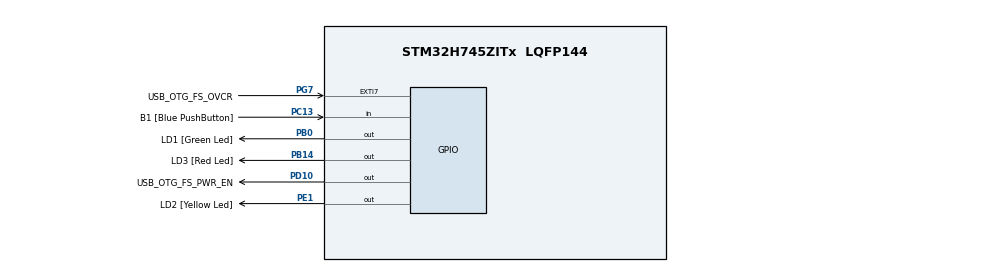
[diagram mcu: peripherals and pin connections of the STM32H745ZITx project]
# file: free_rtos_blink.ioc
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CortexM4.IPs=FATFS_M4\:I,FREERTOS_M4\:I,IWDG2\:I,RCC,WWDG2\:I,DMA,BDMA,MDMA,NVIC2\:I,DEBUG,USB_DEVICE_M4\:I,USB_HOST_M4\:I,PDM2PCM_M4\:I,PWR,RESMGR_UTILITY,SYS_M4\:I,CORTEX_M4\:I,OPENAMP_M4\:I,VREFBUF
CortexM4.Pins=PB0
CortexM7.IPs=FATFS_M7\:I,FREERTOS_M7\:I,IWDG1\:I,RCC\:I,WWDG1\:I,DMA\:I,BDMA\:I,MDMA\:I,NVIC1\:I,SYS\:I,CORTEX_M7\:I,DEBUG\:I,USB_DEVICE_M7\:I,USB_HOST_M7\:I,PDM2PCM_M7\:I,PWR\:I,RESMGR_UTILITY\:I,OPENAMP_M7\:I,VREFBUF\:I,TIM1\:I
CortexM7.Pins=PB14,PE1
FREERTOS_M7.Tasks01=defaultTask,24,128,StartDefaultTask,Default,NULL,Dynamic,NULL,NULL;blinkYellow,8,128,blinkYellowLED,Default,NULL,Dynamic,NULL,NULL;blinkRed,24,128,blinkRedLED,Default,NULL,Dynamic,NULL,NULL
Mcu.Family=STM32H7
Mcu.Name=STM32H745ZITx
Mcu.Package=LQFP144
NVIC1.PriorityGroup=NVIC_PRIORITYGROUP_4
NVIC1.TIM1_UP_IRQn=true\:0\:0\:false\:false\:true\:false\:false\:true
NVIC1.TimeBase=TIM1_UP_IRQn
NVIC1.TimeBaseIP=TIM1
NVIC2.PriorityGroup=NVIC_PRIORITYGROUP_4
PA1.PinAttribute=CortexM4
PA1.Signal=ETH_REF_CLK
PA11.PinAttribute=CortexM7
PA11.Signal=USB_OTG_FS_DM
PA12.PinAttribute=CortexM7
PA12.Signal=USB_OTG_FS_DP
PA2.PinAttribute=CortexM4
PA2.Signal=ETH_MDIO
PA7.PinAttribute=CortexM4
PA7.Signal=ETH_CRS_DV
PA8.PinAttribute=CortexM7
PA8.Signal=USB_OTG_FS_SOF
PA9.PinAttribute=CortexM7
PA9.Signal=USB_OTG_FS_VBUS
PB0.GPIO_Label=LD1 [Green Led]
PB0.GPIO_PuPd=GPIO_PULLUP
PB0.PinAttribute=CortexM4
PB0.PinState=GPIO_PIN_SET
PB0.Signal=GPIO_Output
PB13.PinAttribute=CortexM4
PB13.Signal=ETH_TXD1
PB14.GPIO_Label=LD3 [Red Led]
PB14.PinAttribute=CortexM7
PB14.PinState=GPIO_PIN_RESET
PB14.Signal=GPIO_Output
PC1.PinAttribute=CortexM4
PC1.Signal=ETH_MDC
PC13.GPIO_Label=B1 [Blue PushButton]
PC13.PinAttribute=Free
PC13.Signal=GPIO_Input
PC14-OSC32_IN\ (OSC32_IN).Mode=LSE-External-Oscillator
PC14-OSC32_IN\ (OSC32_IN).PinAttribute=CortexM7
PC14-OSC32_IN\ (OSC32_IN).Signal=RCC_OSC32_IN
PC15-OSC32_OUT\ (OSC32_OUT).Mode=LSE-External-Oscillator
PC15-OSC32_OUT\ (OSC32_OUT).PinAttribute=CortexM7
PC15-OSC32_OUT\ (OSC32_OUT).Signal=RCC_OSC32_OUT
PC4.PinAttribute=CortexM4
PC4.Signal=ETH_RXD0
PC5.PinAttribute=CortexM4
PC5.Signal=ETH_RXD1
PD10.GPIO_Label=USB_OTG_FS_PWR_EN
PD10.PinAttribute=Free
PD10.Signal=GPIO_Output
PD8.GPIO_Label=STLINK_RX
PD8.PinAttribute=CortexM4
PD8.Signal=USART3_TX
PD9.GPIO_Label=STLINK_TX
PD9.PinAttribute=CortexM4
PD9.Signal=USART3_RX
PE1.GPIO_Label=LD2 [Yellow Led]
PE1.PinAttribute=CortexM7
PE1.Signal=GPIO_Output
PG11.PinAttribute=CortexM4
PG11.Signal=ETH_TX_EN
PG13.PinAttribute=CortexM4
PG13.Signal=ETH_TXD0
PG7.GPIO_Label=USB_OTG_FS_OVCR
PG7.PinAttribute=Free
PG7.Signal=GPXTI7
PH0-OSC_IN\ (PH0).Mode=HSE-External-Clock-Source
PH0-OSC_IN\ (PH0).PinAttribute=CortexM7
PH0-OSC_IN\ (PH0).Signal=RCC_OSC_IN
PH1-OSC_OUT\ (PH1).PinAttribute=CortexM7
PH1-OSC_OUT\ (PH1).Signal=RCC_OSC_OUT
ProjectManager.HeapSize=0x200
ProjectManager.StackSize=0x400
ProjectManager.TargetToolchain=STM32CubeIDE
RCC.ADCFreq_Value=16125000
RCC.APB1Freq_Value=120000000
RCC.APB2Freq_Value=120000000
RCC.APB3Freq_Value=120000000
RCC.APB4Freq_Value=120000000
RCC.CortexFreq_Value=480000000
RCC.D1PPRE=RCC_APB3_DIV2
RCC.D2PPRE1=RCC_APB1_DIV2
RCC.D2PPRE2=RCC_APB2_DIV2
RCC.D3PPRE=RCC_APB4_DIV2
RCC.DIVM1=1
RCC.DIVM3=1
RCC.DIVN1=120
RCC.DIVN3=24
RCC.DIVQ3=4
RCC.HCLKFreq_Value=240000000
RCC.HPRE=RCC_HCLK_DIV2
RCC.HSE_VALUE=8000000
RCC.PLL2FRACN=0
RCC.PLL3FRACN=0
RCC.PLLFRACN=0
RCC.PLLSourceVirtual=RCC_PLLSOURCE_HSE
RCC.SYSCLKFreq_VALUE=480000000
RCC.SYSCLKSource=RCC_SYSCLKSOURCE_PLLCLK
RCC.SupplySource=PWR_DIRECT_SMPS_SUPPLY
RCC.USBCLockSelection=RCC_USBCLKSOURCE_PLL3
RCC.USBFreq_Value=48000000
VP_FREERTOS_M7_VS_CMSIS_V2.Mode=CMSIS_V2
VP_SYS_M4_VS_Systick.Mode=SysTick
VP_SYS_VS_tim1.Mode=TIM1
board=NUCLEO-H745ZI-Q

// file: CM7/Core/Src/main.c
/* USER CODE BEGIN Header */
/**
  ******************************************************************************
  * @file           : main.c
  * @brief          : Main program body
  ******************************************************************************
  * @attention
  *
  * <h2><center>&copy; Copyright (c) 2021 STMicroelectronics.
  * All rights reserved.</center></h2>
  *
  * This software component is licensed by ST under BSD 3-Clause license,
  * the "License"; You may not use this file except in compliance with the
  * License. You may obtain a copy of the License at:
  *                        opensource.org/licenses/BSD-3-Clause
  *
  ******************************************************************************
  */
/* USER CODE END Header */
#include "main.h"
#include "cmsis_os.h"

/* USER CODE BEGIN PD */

#ifndef HSEM_ID_0
#define HSEM_ID_0 (0U) /* HW semaphore 0*/
#endif
/* USER CODE END PD */

/* Definitions for defaultTask */
osThreadId_t defaultTaskHandle;
const osThreadAttr_t defaultTask_attributes = {
  .name = "defaultTask",
  .priority = (osPriority_t) osPriorityNormal,
  .stack_size = 128 * 4
};
/* Definitions for blinkYellow */
osThreadId_t blinkYellowHandle;
const osThreadAttr_t blinkYellow_attributes = {
  .name = "blinkYellow",
  .priority = (osPriority_t) osPriorityLow,
  .stack_size = 128 * 4
};
/* Definitions for blinkRed */
osThreadId_t blinkRedHandle;
const osThreadAttr_t blinkRed_attributes = {
  .name = "blinkRed",
  .priority = (osPriority_t) osPriorityNormal,
  .stack_size = 128 * 4
};

void SystemClock_Config(void);
static void MX_GPIO_Init(void);
void StartDefaultTask(void *argument);
void blinkYellowLED(void *argument);
void blinkRedLED(void *argument);

int main(void)
{
/* USER CODE BEGIN Boot_Mode_Sequence_0 */
  int32_t timeout;
/* USER CODE END Boot_Mode_Sequence_0 */

/* USER CODE BEGIN Boot_Mode_Sequence_1 */
  /* Wait until CPU2 boots and enters in stop mode or timeout*/
  timeout = 0xFFFF;
  while((__HAL_RCC_GET_FLAG(RCC_FLAG_D2CKRDY) != RESET) && (timeout-- > 0));
  if ( timeout < 0 )
  {
  Error_Handler();
  }
/* USER CODE END Boot_Mode_Sequence_1 */
  /* MCU Configuration--------------------------------------------------------*/

  /* Reset of all peripherals, Initializes the Flash interface and the Systick. */
  HAL_Init();

  /* Configure the system clock */
  SystemClock_Config();
/* USER CODE BEGIN Boot_Mode_Sequence_2 */
/* When system initialization is finished, Cortex-M7 will release Cortex-M4 by means of
HSEM notification */
/*HW semaphore Clock enable*/
__HAL_RCC_HSEM_CLK_ENABLE();
/*Take HSEM */
HAL_HSEM_FastTake(HSEM_ID_0);
/*Release HSEM in order to notify the CPU2(CM4)*/
HAL_HSEM_Release(HSEM_ID_0,0);
/* wait until CPU2 wakes up from stop mode */
timeout = 0xFFFF;
while((__HAL_RCC_GET_FLAG(RCC_FLAG_D2CKRDY) == RESET) && (timeout-- > 0));
if ( timeout < 0 )
{
Error_Handler();
}
/* USER CODE END Boot_Mode_Sequence_2 */

  /* Initialize all configured peripherals */
  MX_GPIO_Init();

  /* Init scheduler */
  osKernelInitialize();

  /* Create the thread(s) */
  /* creation of defaultTask */
  defaultTaskHandle = osThreadNew(StartDefaultTask, NULL, &defaultTask_attributes);

  /* creation of blinkYellow */
  blinkYellowHandle = osThreadNew(blinkYellowLED, NULL, &blinkYellow_attributes);

  /* creation of blinkRed */
  blinkRedHandle = osThreadNew(blinkRedLED, NULL, &blinkRed_attributes);

  /* Start scheduler */
  osKernelStart();

  /* We should never get here as control is now taken by the scheduler */
  /* Infinite loop */
  while (1)
  {

  }
}

void SystemClock_Config(void)
{
  RCC_OscInitTypeDef RCC_OscInitStruct = {0};
  RCC_ClkInitTypeDef RCC_ClkInitStruct = {0};

  /** Supply configuration update enable
  */
  HAL_PWREx_ConfigSupply(PWR_DIRECT_SMPS_SUPPLY);
  /** Configure the main internal regulator output voltage
  */
  __HAL_PWR_VOLTAGESCALING_CONFIG(PWR_REGULATOR_VOLTAGE_SCALE0);

  while(!__HAL_PWR_GET_FLAG(PWR_FLAG_VOSRDY)) {}
  /** Initializes the RCC Oscillators according to the specified parameters
  * in the RCC_OscInitTypeDef structure.
  */
  RCC_OscInitStruct.OscillatorType = RCC_OSCILLATORTYPE_HSE;
  RCC_OscInitStruct.HSEState = RCC_HSE_BYPASS;
  RCC_OscInitStruct.PLL.PLLState = RCC_PLL_ON;
  RCC_OscInitStruct.PLL.PLLSource = RCC_PLLSOURCE_HSE;
  RCC_OscInitStruct.PLL.PLLM = 1;
  RCC_OscInitStruct.PLL.PLLN = 120;
  RCC_OscInitStruct.PLL.PLLP = 2;
  RCC_OscInitStruct.PLL.PLLQ = 2;
  RCC_OscInitStruct.PLL.PLLR = 2;
  RCC_OscInitStruct.PLL.PLLRGE = RCC_PLL1VCIRANGE_3;
  RCC_OscInitStruct.PLL.PLLVCOSEL = RCC_PLL1VCOWIDE;
  RCC_OscInitStruct.PLL.PLLFRACN = 0;
  if (HAL_RCC_OscConfig(&RCC_OscInitStruct) != HAL_OK)
  {
    Error_Handler();
  }
  /** Initializes the CPU, AHB and APB buses clocks
  */
  RCC_ClkInitStruct.ClockType = RCC_CLOCKTYPE_HCLK|RCC_CLOCKTYPE_SYSCLK
                              |RCC_CLOCKTYPE_PCLK1|RCC_CLOCKTYPE_PCLK2
                              |RCC_CLOCKTYPE_D3PCLK1|RCC_CLOCKTYPE_D1PCLK1;
  RCC_ClkInitStruct.SYSCLKSource = RCC_SYSCLKSOURCE_PLLCLK;
  RCC_ClkInitStruct.SYSCLKDivider = RCC_SYSCLK_DIV1;
  RCC_ClkInitStruct.AHBCLKDivider = RCC_HCLK_DIV2;
  RCC_ClkInitStruct.APB3CLKDivider = RCC_APB3_DIV2;
  RCC_ClkInitStruct.APB1CLKDivider = RCC_APB1_DIV2;
  RCC_ClkInitStruct.APB2CLKDivider = RCC_APB2_DIV2;
  RCC_ClkInitStruct.APB4CLKDivider = RCC_APB4_DIV2;

  if (HAL_RCC_ClockConfig(&RCC_ClkInitStruct, FLASH_LATENCY_4) != HAL_OK)
  {
    Error_Handler();
  }
}

static void MX_GPIO_Init(void)
{
  GPIO_InitTypeDef GPIO_InitStruct = {0};

  /* GPIO Ports Clock Enable */
  __HAL_RCC_GPIOC_CLK_ENABLE();
  __HAL_RCC_GPIOH_CLK_ENABLE();
  __HAL_RCC_GPIOB_CLK_ENABLE();
  __HAL_RCC_GPIOE_CLK_ENABLE();

  /*Configure GPIO pin Output Level */
  HAL_GPIO_WritePin(LD3_GPIO_Port, LD3_Pin, GPIO_PIN_RESET);

  /*Configure GPIO pin Output Level */
  HAL_GPIO_WritePin(LD2_GPIO_Port, LD2_Pin, GPIO_PIN_RESET);

  /*Configure GPIO pin : LD3_Pin */
  GPIO_InitStruct.Pin = LD3_Pin;
  GPIO_InitStruct.Mode = GPIO_MODE_OUTPUT_PP;
  GPIO_InitStruct.Pull = GPIO_NOPULL;
  GPIO_InitStruct.Speed = GPIO_SPEED_FREQ_LOW;
  HAL_GPIO_Init(LD3_GPIO_Port, &GPIO_InitStruct);

  /*Configure GPIO pin : LD2_Pin */
  GPIO_InitStruct.Pin = LD2_Pin;
  GPIO_InitStruct.Mode = GPIO_MODE_OUTPUT_PP;
  GPIO_InitStruct.Pull = GPIO_NOPULL;
  GPIO_InitStruct.Speed = GPIO_SPEED_FREQ_LOW;
  HAL_GPIO_Init(LD2_GPIO_Port, &GPIO_InitStruct);

}

void StartDefaultTask(void *argument)
{
  for(;;)
  {
    osDelay(1);
  }
}

void blinkYellowLED(void *argument)
{
  /* USER CODE BEGIN blinkYellowLED */
  /* Infinite loop */
  for(;;) {
	  HAL_GPIO_TogglePin(GPIOE, GPIO_PIN_1);
	  osDelay(250);
  }
  /* USER CODE END blinkYellowLED */
}

void blinkRedLED(void *argument)
{
  /* USER CODE BEGIN blinkRedLED */
  /* Infinite loop */
  for(;;) {
	  int i = 0;
	  HAL_GPIO_TogglePin(GPIOB, GPIO_PIN_14);
	  for (i = 0; i < 999999; i++) {
		  //something expensive
	  }
	  osDelay(500);
  }
  /* USER CODE END blinkRedLED */
}

 /**
  * @brief  Period elapsed callback in non blocking mode
  * @note   This function is called  when TIM1 interrupt took place, inside
  * HAL_TIM_IRQHandler(). It makes a direct call to HAL_IncTick() to increment
  * a global variable "uwTick" used as application time base.
  * @param  htim : TIM handle
  * @retval None
  */
void HAL_TIM_PeriodElapsedCallback(TIM_HandleTypeDef *htim)
{
  if (htim->Instance == TIM1) {
    HAL_IncTick();
  }
}

void Error_Handler(void)
{
  __disable_irq();
  while (1)
  {
  }
}

/************************ (C) COPYRIGHT STMicroelectronics *****END OF FILE****/
